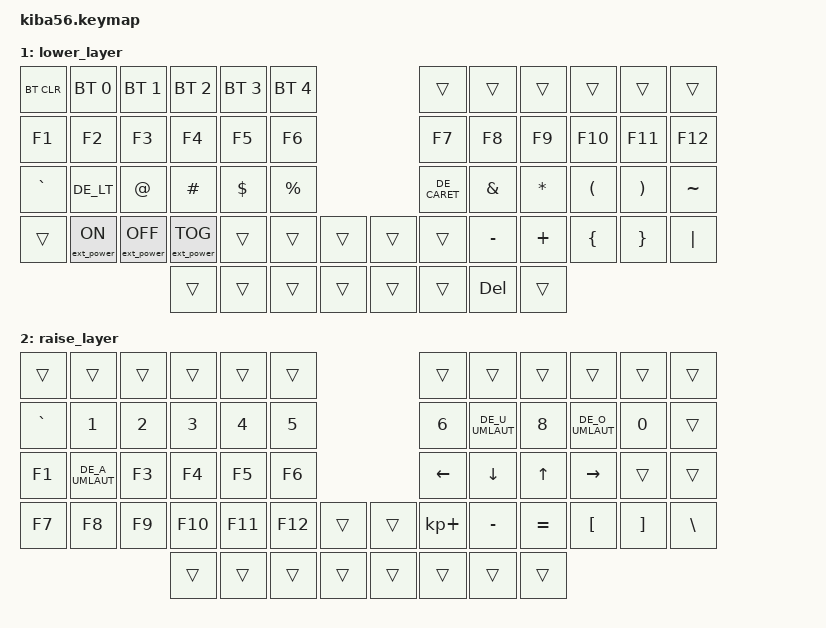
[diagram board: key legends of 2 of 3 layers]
/*
 * Copyright (c) 2020 The ZMK Contributors
 *
 * SPDX-License-Identifier: MIT
 */

#include <behaviors.dtsi>
#include <dt-bindings/zmk/keys.h>
#include <dt-bindings/zmk/bt.h>
#include <dt-bindings/zmk/ext_power.h>
#include "keys_de.h"

/ {
    keymap {
        compatible = "zmk,keymap";

        default_layer {
// ------------------------------------------------------------------------------------------------------------
// |  ESC  |  1  |  2  |  3   |  4   |  5   |                   |  6   |  7    |  8    |  9   |   0   |   `   |
// |  TAB  |  Q  |  W  |  E   |  R   |  T   |                   |  Z   |  U    |  I    |  O   |   P   |   +   |
// |  CTRL |  A  |  S  |  D   |  F   |  G   |                   |  H   |  J    |  K    |  L   |   ß   |   #   |
// | SHIFT |  Y  |  X  |  C   |  V   |  B   |                   |  N   |  M    |  ,    |  .   |   -   | SHIFT |
//                     | GUI  | ALTGR| LOWER|  SPACE |  | ENTER | RAISE| BSPC  | GUI   |
            bindings = <
&kp ESC   &kp DE_N1 &kp DE_N2 &kp DE_N3   &kp DE_N4   &kp DE_N5                     &kp DE_N6 &kp DE_N7   &kp DE_N8    &kp DE_N9  &kp DE_N0   &kp DE_GRAVE
&kp TAB   &kp DE_Q  &kp DE_W  &kp DE_E    &kp DE_R    &kp DE_T                      &kp DE_Z  &kp DE_U    &kp DE_I     &kp DE_O   &kp DE_P    &kp DE_PLUS
&kp LCTRL &kp DE_A  &kp DE_S  &kp DE_D    &kp DE_F    &kp DE_G                      &kp DE_H  &kp DE_J    &kp DE_K     &kp DE_L   &kp DE_SZ &kp DE_HASH
&kp LSHFT &kp DE_Y  &kp DE_X  &kp DE_C    &kp DE_V    &kp DE_B                      &kp DE_N  &kp DE_M    &kp DE_COMMA &kp DE_DOT &kp DE_MINUS &kp RSHFT
                        &kp LGUI &kp RALT &mo 1  &kp SPACE  &kp RET  &mo 2  &kp BSPC &kp RGUI
            >;
        };

        lower_layer {
// ------------------------------------------------------------------------------------------------------------
// | BTCLR | BT1 | BT2 |  BT3 |  BT4 |  BT5 |                   |      |       |       |      |       |       |
// |  F1   |  F2 |  F3 |  F4  |  F5  |  F6  |                   |  F7  |  F8   |  F9   |  F10 |  F11  |  F12  |
// |   `   |  <  |  @  |  #   |  $   |  %   |                   |  ^   |  &    |  *    |  (   |   )   |   ~   |
// |       |     |     |      |      |      |                   |      |  _    |  +    |  {   |   }   |  "|"  |
//                     |      |      |      |        |  |       |      | ENTF  |       |
            bindings = <
&bt BT_CLR &bt BT_SEL 0     &bt BT_SEL 1      &bt BT_SEL 2      &bt BT_SEL 3 &bt BT_SEL 4                 &trans    &trans    &trans    &trans    &trans    &trans
&kp F1     &kp F2           &kp F3            &kp F4            &kp F5       &kp F6                       &kp F7    &kp F8    &kp F9    &kp F10   &kp F11   &kp F12
&kp GRAVE  &kp DE_LT        &kp AT            &kp HASH          &kp DOLLAR   &kp PRCNT                    &kp DE_CARET &kp AMPS  &kp ASTRK &kp LPAR  &kp RPAR  &kp TILDE
&trans     &ext_power EP_ON &ext_power EP_OFF &ext_power EP_TOG &trans       &trans    &trans   &trans    &trans    &kp MINUS &kp PLUS  &kp LBRC  &kp RBRC  &kp PIPE
                                              &trans            &trans       &trans    &trans   &trans    &trans    &kp DEL   &trans
            >;
        };

        raise_layer {
// ------------------------------------------------------------------------------------------------------------
// |       |     |     |      |      |      |                   |      |       |       |      |       |       |
// |   `   |  1  |  2  |  3   |  4   |  5   |                   |  6   |   7   |   8   |  Ö   |   0   |       |
// |   F1  |  Ä  |  F3 |  F4  |  F5  |  F6  |                   |  <   |   v   |   ^   |  ->  |       |       |
// |   F7  |  F8 |  F9 |  F10 |  F11 |  F12 |                   |  +   |   -   |   =   |  [   |   ]   |   \   |
//                     |      |      |      |        |  |       |      |       |       |
            bindings = <
&trans    &trans &trans &trans  &trans  &trans                       &trans      &trans    &trans    &trans    &trans    &trans
&kp GRAVE &kp N1 &kp N2 &kp N3  &kp N4  &kp N5                       &kp N6      &kp DE_U_UMLAUT    &kp N8    &kp DE_O_UMLAUT    &kp N0    &trans
&kp F1    &kp DE_A_UMLAUT &kp F3 &kp F4  &kp F5  &kp F6                       &kp LEFT    &kp DOWN  &kp UP    &kp RIGHT &trans    &trans
&kp F7    &kp F8 &kp F9 &kp F10 &kp F11 &kp F12   &trans   &trans    &kp KP_PLUS &kp MINUS &kp EQUAL &kp LBKT  &kp RBKT  &kp BSLH
                        &trans  &trans  &trans    &trans   &trans    &trans      &trans    &trans
            >;
        };
    };
};
